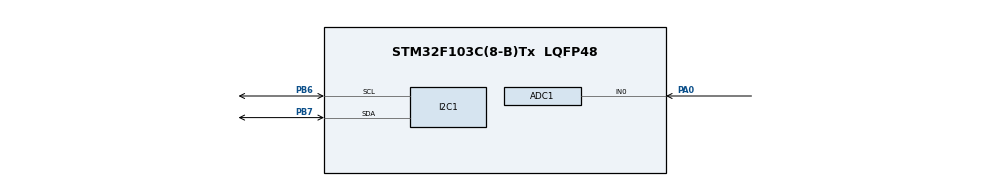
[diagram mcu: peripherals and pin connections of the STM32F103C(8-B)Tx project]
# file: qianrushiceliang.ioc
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ADC1.Channel-0\#ChannelRegularConversion=ADC_CHANNEL_0
ADC1.NbrOfConversionFlag=1
ADC1.Rank-0\#ChannelRegularConversion=1
ADC1.SamplingTime-0\#ChannelRegularConversion=ADC_SAMPLETIME_239CYCLES_5
ADC1.master=1
Mcu.Family=STM32F1
Mcu.Name=STM32F103C(8-B)Tx
Mcu.Package=LQFP48
NVIC.PriorityGroup=NVIC_PRIORITYGROUP_4
PA0-WKUP.Signal=ADCx_IN0
PA13.Mode=Serial_Wire
PA13.Signal=SYS_JTMS-SWDIO
PA14.Mode=Serial_Wire
PA14.Signal=SYS_JTCK-SWCLK
PB6.Mode=I2C
PB6.Signal=I2C1_SCL
PB7.Mode=I2C
PB7.Signal=I2C1_SDA
ProjectManager.HeapSize=0x200
ProjectManager.StackSize=0x400
ProjectManager.TargetToolchain=MDK-ARM V5.32
RCC.APB1Freq_Value=8000000
RCC.APB2Freq_Value=8000000
SH.ADCx_IN0.0=ADC1_IN0,IN0
board=custom

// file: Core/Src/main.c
/* USER CODE BEGIN Header */
/**
  ******************************************************************************
  * @file           : main.c
  * @brief          : Main program body
  ******************************************************************************
  * @attention
  *
  * Copyright (c) 2026 STMicroelectronics.
  * All rights reserved.
  *
  * This software is licensed under terms that can be found in the LICENSE file
  * in the root directory of this software component.
  * If no LICENSE file comes with this software, it is provided AS-IS.
  *
  ******************************************************************************
  */
/* USER CODE END Header */
#include "main.h"
#include "adc.h"
#include "i2c.h"
#include "gpio.h"
#include "oled.h"
#include <stdio.h>

void SystemClock_Config(void);

/* USER CODE BEGIN 0 */
/* USER CODE BEGIN 0 */

volatile uint8_t found_addr = 0;
volatile uint8_t i2c_scan_done = 0;
volatile uint8_t scan_addr = 0;

uint32_t adc_raw = 0;
float v_adc = 0.0f;
float v_in = 0.0f;

#define R1_K 100.3f
#define R2_K 15.66f
#define ADC_REF 3.3f
#define CAL_K 1.072f;
char line1[24];
char line2[24];
char line3[24];
/* USER CODE END 0 */
/* USER CODE END 0 */

int main(void)
{

  /* MCU Configuration--------------------------------------------------------*/

  /* Reset of all peripherals, Initializes the Flash interface and the Systick. */
  HAL_Init();

  /* Configure the system clock */
  SystemClock_Config();

  /* Initialize all configured peripherals */
  MX_GPIO_Init();
  MX_ADC1_Init();
  MX_I2C1_Init();
OLED_Init();
OLED_Clear();
OLED_ShowString(0, 0, "OLED OK");
OLED_ShowString(2, 0, "Voltage Meter");
HAL_Delay(1000);

  /* Infinite loop */
  /* USER CODE BEGIN WHILE */
  while (1)
  {
		HAL_ADC_Start(&hadc1);

if (HAL_ADC_PollForConversion(&hadc1, 10) == HAL_OK)
{
    adc_raw = HAL_ADC_GetValue(&hadc1);
}

HAL_ADC_Stop(&hadc1);

v_adc = adc_raw / 4095.0f * ADC_REF;
v_in  = v_adc * (R1_K + R2_K) / R2_K;
v_in=v_in*CAL_K;
 sprintf(line1, "Voltage Meter");
    sprintf(line2, "Vin: %.2f V", v_in);
    sprintf(line3, "ADC: %lu", adc_raw);

    OLED_Clear();
    OLED_ShowString(0, 0, line1);
    OLED_ShowString(2, 0, line2);
    OLED_ShowString(4, 0, line3);

//HAL_Delay(200);
    /* USER CODE END WHILE */

    /* USER CODE BEGIN 3 */
//if (i2c_scan_done == 0)
//{
//    for (uint8_t addr = 1; addr < 127; addr++)
//    {
//        if (HAL_I2C_IsDeviceReady(&hi2c1, addr << 1, 2, 10) == HAL_OK)
//        {
//            found_addr = addr;
//            break;
//        }
//    }

//    i2c_scan_done = 1;
//}

HAL_Delay(500);
  }
  /* USER CODE END 3 */
}

void SystemClock_Config(void)
{
  RCC_OscInitTypeDef RCC_OscInitStruct = {0};
  RCC_ClkInitTypeDef RCC_ClkInitStruct = {0};
  RCC_PeriphCLKInitTypeDef PeriphClkInit = {0};

  /** Initializes the RCC Oscillators according to the specified parameters
  * in the RCC_OscInitTypeDef structure.
  */
  RCC_OscInitStruct.OscillatorType = RCC_OSCILLATORTYPE_HSI;
  RCC_OscInitStruct.HSIState = RCC_HSI_ON;
  RCC_OscInitStruct.HSICalibrationValue = RCC_HSICALIBRATION_DEFAULT;
  RCC_OscInitStruct.PLL.PLLState = RCC_PLL_NONE;
  if (HAL_RCC_OscConfig(&RCC_OscInitStruct) != HAL_OK)
  {
    Error_Handler();
  }

  /** Initializes the CPU, AHB and APB buses clocks
  */
  RCC_ClkInitStruct.ClockType = RCC_CLOCKTYPE_HCLK|RCC_CLOCKTYPE_SYSCLK
                              |RCC_CLOCKTYPE_PCLK1|RCC_CLOCKTYPE_PCLK2;
  RCC_ClkInitStruct.SYSCLKSource = RCC_SYSCLKSOURCE_HSI;
  RCC_ClkInitStruct.AHBCLKDivider = RCC_SYSCLK_DIV1;
  RCC_ClkInitStruct.APB1CLKDivider = RCC_HCLK_DIV1;
  RCC_ClkInitStruct.APB2CLKDivider = RCC_HCLK_DIV1;

  if (HAL_RCC_ClockConfig(&RCC_ClkInitStruct, FLASH_LATENCY_0) != HAL_OK)
  {
    Error_Handler();
  }
  PeriphClkInit.PeriphClockSelection = RCC_PERIPHCLK_ADC;
  PeriphClkInit.AdcClockSelection = RCC_ADCPCLK2_DIV2;
  if (HAL_RCCEx_PeriphCLKConfig(&PeriphClkInit) != HAL_OK)
  {
    Error_Handler();
  }
}

void Error_Handler(void)
{
  __disable_irq();
  while (1)
  {
  }
}
